# MKE14F16 register map
Vendor: Freescale Semiconductor, Inc.; Series: Kinetis_E; File version: 1.6
CPU: CM4 r0p1, little endian, no MPU, FPU, VTOR, 4 interrupt priority bits
Registers are 32-bit, read-write, reset 0x0 unless marked. A register's access mark holds for its fields unless they carry their own. Offsets are from the block's base; [hi:lo] are bit positions; {n}, {i} and the like mark numbered series; 'fields as' and 'values as' point back to an identical list.

## FTFE_FlashConfig — Flash configuration field
Base 0x00000400; register names take the prefix NV_
0x00 BACKKEY3 8-bit ro reset 0xFF — Backdoor Comparison Key 3.
  [7:0] KEY — Backdoor Comparison Key.
0x01 BACKKEY2 8-bit ro reset 0xFF — Backdoor Comparison Key 2.
  [7:0] KEY — Backdoor Comparison Key.
0x02 BACKKEY1 8-bit ro reset 0xFF — Backdoor Comparison Key 1.
  [7:0] KEY — Backdoor Comparison Key.
0x03 BACKKEY0 8-bit ro reset 0xFF — Backdoor Comparison Key 0.
  [7:0] KEY — Backdoor Comparison Key.
0x04 BACKKEY7 8-bit ro reset 0xFF — Backdoor Comparison Key 7.
  [7:0] KEY — Backdoor Comparison Key.
0x05 BACKKEY6 8-bit ro reset 0xFF — Backdoor Comparison Key 6.
  [7:0] KEY — Backdoor Comparison Key.
0x06 BACKKEY5 8-bit ro reset 0xFF — Backdoor Comparison Key 5.
  [7:0] KEY — Backdoor Comparison Key.
0x07 BACKKEY4 8-bit ro reset 0xFF — Backdoor Comparison Key 4.
  [7:0] KEY — Backdoor Comparison Key.
0x08 FPROT3 8-bit ro reset 0xFF — Non-volatile P-Flash Protection 1 - Low Register
  [7:0] PROT — P-Flash Region Protect
0x09 FPROT2 8-bit ro reset 0xFF — Non-volatile P-Flash Protection 1 - High Register
  [7:0] PROT — P-Flash Region Protect
0x0A FPROT1 8-bit ro reset 0xFF — Non-volatile P-Flash Protection 0 - Low Register
  [7:0] PROT — P-Flash Region Protect
0x0B FPROT0 8-bit ro reset 0xFF — Non-volatile P-Flash Protection 0 - High Register
  [7:0] PROT — P-Flash Region Protect
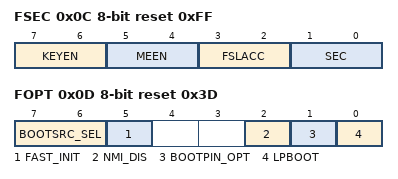
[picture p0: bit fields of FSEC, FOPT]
0x0C FSEC 8-bit ro reset 0xFF — Non-volatile Flash Security Register
  [7:6] KEYEN — Backdoor Key Security Enable
    2=Backdoor key access enabled; 3=Backdoor key access disabled
  [5:4] MEEN
    2=Mass erase is disabled; 3=Mass erase is enabled
  [3:2] FSLACC — Freescale Failure Analysis Access Code
    2=Freescale factory access denied; 3=Freescale factory access granted
  [1:0] SEC — Flash Security
    2=MCU security status is unsecure; 3=MCU security status is secure
0x0D FOPT 8-bit ro reset 0x3D — Non-volatile Flash Option Register
  [7:6] BOOTSRC_SEL — Boot source selection
    0=Boot from Flash; 2=Boot from ROM; 3=Boot from ROM
  [5] FAST_INIT
    0=Slower initialization; 1=Fast Initialization
  [2] NMI_DIS
    0=NMI interrupts are always blocked; 1=NMI_b pin/interrupts reset default to enabled
  [1] BOOTPIN_OPT
    0=Force Boot from ROM if BOOTCFG0 asserted, where BOOTCFG0 is the boot config function which is muxed with NMI pin; 1=Boot source configured by FOPT (BOOTSRC_SEL) bits
  [0] LPBOOT
    0=Low-power boot; 1=Normal boot
0x0E FEPROT 8-bit ro reset 0xFF — Non-volatile EERAM Protection Register
  [7:0] EPROT
0x0F FDPROT 8-bit ro reset 0xFF — Non-volatile D-Flash Protection Register
  [7:0] DPROT — D-Flash Region Protect

## AIPS — AIPS-Lite Bridge
Base 0x40000000; register names take the prefix AIPS_
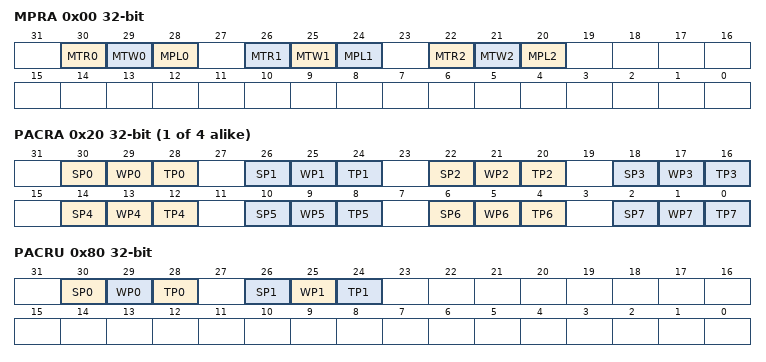
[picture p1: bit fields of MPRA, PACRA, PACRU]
0x00 MPRA — Master Privilege Register A
  [30] MTR0 — Master 0 Trusted For Read
    0=This master is not trusted for read accesses; 1=This master is trusted for read accesses
  [29] MTW0 — Master 0 Trusted For Writes
    0=This master is not trusted for write accesses; 1=This master is trusted for write accesses
  [28] MPL0 — Master 0 Privilege Level
    0=Accesses from this master are forced to user-mode; 1=Accesses from this master are not forced to user-mode
  [26] MTR1 — Master 1 Trusted for Read
    values as MTR0
  [25] MTW1 — Master 1 Trusted for Writes
    values as MTW0
  [24] MPL1 — Master 1 Privilege Level
    values as MPL0
  [22] MTR2 — Master 2 Trusted For Read
    values as MTR0
  [21] MTW2 — Master 2 Trusted For Writes
    values as MTW0
  [20] MPL2 — Master 2 Privilege Level
    values as MPL0
0x20 PACR{x} (x=A,B,C,D; step 0x4) — Peripheral Access Control Register
  [30-4n] SP{n} (n=0..7) — Supervisor Protect
    0=This peripheral does not require supervisor privilege level for accesses; 1=This peripheral requires supervisor privilege level for accesses
  [29-4n] WP{n} (n=0..7) — Write Protect
    0=This peripheral allows write accesses; 1=This peripheral is write protected
  [28-4n] TP{n} (n=0..7) — Trusted Protect
    0=Accesses from an untrusted master are allowed; 1=Accesses from an untrusted master are not allowed
0x40 OPACR{x} (x=A,B,C,D,E,F,G,H,I,J,K,L,M,N,O,P; step 0x4) — Off-Platform Peripheral Access Control Register
  fields as PACR{x}
0x80 PACRU — Peripheral Access Control Register
  [30] SP0 — Supervisor Protect
    values as PACR{x}.SP0
  [29] WP0 — Write Protect
    values as PACR{x}.WP0
  [28] TP0 — Trusted Protect
    values as PACR{x}.TP0
  [26] SP1 — Supervisor Protect
    values as PACR{x}.SP0
  [25] WP1 — Write Protect
    values as PACR{x}.WP0
  [24] TP1 — Trusted Protect
    values as PACR{x}.TP0

## Notices in the file
Redistribution and use in source and binary forms, with or without modification,
are permitted provided that the following conditions are met:
o Redistributions of source code must retain the above copyright notice, this list
of conditions and the following disclaimer.
o Redistributions in binary form must reproduce the above copyright notice, this
list of conditions and the following disclaimer in the documentation and/or
other materials provided with the distribution.
o Neither the name of Freescale Semiconductor, Inc. nor the names of its
contributors may be used to endorse or promote products derived from this
software without specific prior written permission.
THIS SOFTWARE IS PROVIDED BY THE COPYRIGHT HOLDERS AND CONTRIBUTORS "AS IS" AND
ANY EXPRESS OR IMPLIED WARRANTIES, INCLUDING, BUT NOT LIMITED TO, THE IMPLIED
WARRANTIES OF MERCHANTABILITY AND FITNESS FOR A PARTICULAR PURPOSE ARE
DISCLAIMED. IN NO EVENT SHALL THE COPYRIGHT HOLDER OR CONTRIBUTORS BE LIABLE FOR
ANY DIRECT, INDIRECT, INCIDENTAL, SPECIAL, EXEMPLARY, OR CONSEQUENTIAL DAMAGES
(INCLUDING, BUT NOT LIMITED TO, PROCUREMENT OF SUBSTITUTE GOODS OR SERVICES;
LOSS OF USE, DATA, OR PROFITS; OR BUSINESS INTERRUPTION) HOWEVER CAUSED AND ON
ANY THEORY OF LIABILITY, WHETHER IN CONTRACT, STRICT LIABILITY, OR TORT
(INCLUDING NEGLIGENCE OR OTHERWISE) ARISING IN ANY WAY OUT OF THE USE OF THIS
SOFTWARE, EVEN IF ADVISED OF THE POSSIBILITY OF SUCH DAMAGE.
